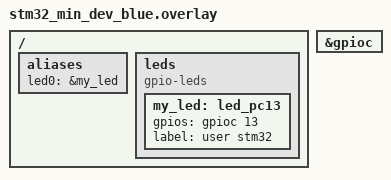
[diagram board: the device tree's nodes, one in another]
/ {
    aliases {
        led0 = &my_led;
    };
    leds {
        compatible = "gpio-leds";

        my_led: led_pc13 {
            gpios = <&gpioc 13 GPIO_ACTIVE_HIGH>;

            label = "user stm32";
        };
    };
};

&gpioc {
    status = "okay";
};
